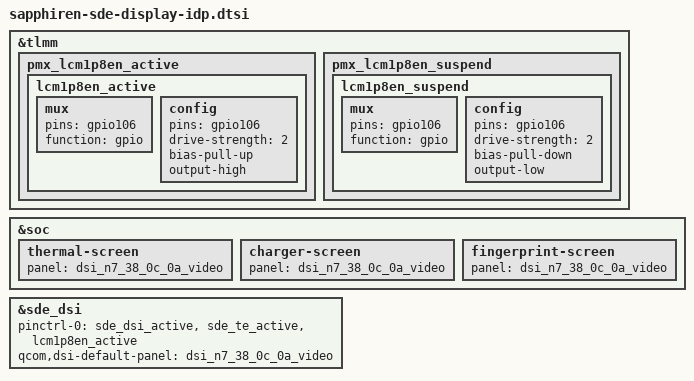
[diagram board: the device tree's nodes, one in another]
#include "dsi_panel_n7_38_0c_0a_fhdp_video.dtsi"
#include "dsi-panel-m7-38-0c-0a-fhdp-video.dtsi"
#include "dsi-panel-m7-38-0c-0b-fhdp-video.dtsi"
#include "xiaomi-sm6225-common.dtsi"
#include "touchscreen_n7.dtsi"
#include "khaje-sde-display-idp.dtsi"

&tlmm {
	pmx_lcm1p8en_active {
		lcm1p8en_active: lcm1p8en_active {
			mux {
				pins = "gpio106";
				function = "gpio";
			};

			config {
				pins = "gpio106";
				drive-strength = <2>;
				bias-pull-up;
				output-high;
			};
		};
	};

	pmx_lcm1p8en_suspend {
		lcm1p8en_suspend: lcm1p8en_suspend {
			mux {
				pins = "gpio106";
				function = "gpio";
			};

			config {
				pins = "gpio106";
				drive-strength = <2>;
				bias-pull-down;
				output-low;
			};
		};
	};
};

&soc {
	thermal-screen {
		panel = <&dsi_n7_38_0c_0a_video>;
	};

	charger-screen {
		panel = <&dsi_n7_38_0c_0a_video>;
	};

	fingerprint-screen {
		panel = <&dsi_n7_38_0c_0a_video>;
	};
};

&sde_dsi {
    pinctrl-0 = <&sde_dsi_active &sde_te_active &lcm1p8en_active>;
    qcom,dsi-default-panel = <&dsi_n7_38_0c_0a_video>;
};
